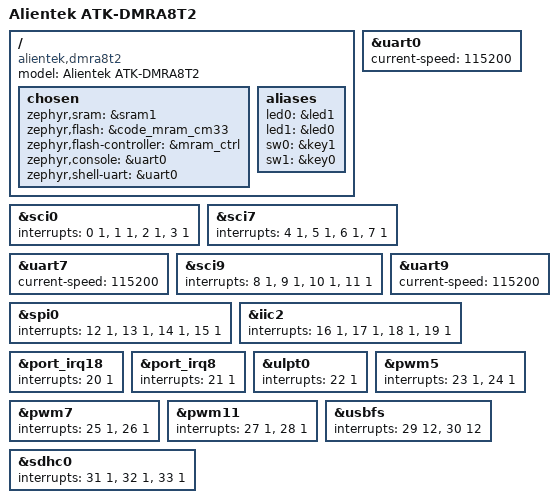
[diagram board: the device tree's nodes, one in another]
/*
 * Copyright (c) 2026 Alientek
 * SPDX-License-Identifier: Apache-2.0
 */

/dts-v1/;

#include <renesas/ra/ra8/r7ka8t2lflcac_cm33.dtsi>
#include "dmra8t2.dtsi"

/ {
	model = "Alientek ATK-DMRA8T2";
	compatible = "alientek,dmra8t2", "renesas,ra8t2", "renesas,ra8";

	chosen {
		zephyr,sram = &sram1;
		zephyr,flash = &code_mram_cm33;
		zephyr,flash-controller = &mram_ctrl;
		zephyr,console = &uart0;
		zephyr,shell-uart = &uart0;
	};

	aliases {
		led0 = &led1;
		led1 = &led0;
		sw0 = &key1;
		sw1 = &key0;
	};
};

/* USB to serial converter (CH343P) on USB-C J3 */
&sci0 {
	interrupts = <0 1>, <1 1>, <2 1>, <3 1>;
	interrupt-names = "rxi", "txi", "tei", "eri";
	status = "okay";
};

&uart0 {
	current-speed = <115200>;
	status = "okay";
};

/* HMI serial screen (CN3) / RS232, selected by jumper P1 */
&sci7 {
	interrupts = <4 1>, <5 1>, <6 1>, <7 1>;
	interrupt-names = "rxi", "txi", "tei", "eri";
};

&uart7 {
	current-speed = <115200>;
};

/* RS485 (TP8485E) on CN2 */
&sci9 {
	interrupts = <8 1>, <9 1>, <10 1>, <11 1>;
	interrupt-names = "rxi", "txi", "tei", "eri";
};

&uart9 {
	current-speed = <115200>;
};

/* SPI LCD / 2.4G wireless module header (U3) */
&spi0 {
	interrupts = <12 1>, <13 1>, <14 1>, <15 1>;
	interrupt-names = "rxi", "txi", "tei", "eri";
};

/* Brought out on the encoder header CN11 (ENC3 = SCL, ENC4 = SDA) */
&iic2 {
	interrupts = <16 1>, <17 1>, <18 1>, <19 1>;
	interrupt-names = "rxi", "txi", "tei", "eri";
};

/* KEY1 = PD06 (IRQ18), KEY0 = P707 (IRQ8) */
&port_irq18 {
	interrupts = <20 1>;
	status = "okay";
};

&port_irq8 {
	interrupts = <21 1>;
	status = "okay";
};

&ulpt0 {
	interrupts = <22 1>;
	interrupt-names = "ulpti";
};

/* Servo 1 pulse (SRV1) */
&pwm5 {
	interrupts = <23 1>, <24 1>;
	interrupt-names = "gtioca", "overflow";
};

/* Servo 2 pulse (SRV2) */
&pwm7 {
	interrupts = <25 1>, <26 1>;
	interrupt-names = "gtioca", "overflow";
};

/* Stepper driver pulse outputs: channel A = ST1_PUL, channel B = ST2_PUL */
&pwm11 {
	interrupts = <27 1>, <28 1>;
	interrupt-names = "gtioca", "overflow";
};

/* USB device on USB-C J4 */
&usbfs {
	interrupts = <29 12>, <30 12>;
	interrupt-names = "usbfs-i", "usbfs-r";
};

/* micro SD card socket */
&sdhc0 {
	interrupts = <31 1>, <32 1>, <33 1>;
	interrupt-names = "accs", "card", "dma-req";
};
